# iostm32f105xx register map
Registers are 32-bit, access not given, no defined reset value unless marked. A register's access mark holds for its fields unless they carry their own. Addresses are absolute; registers are grouped by the start of their names; [hi:lo] are bit positions; {n}, {i} and the like mark numbered series.

## UART4
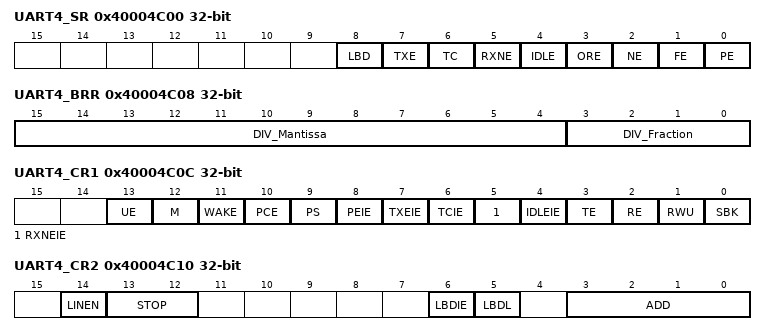
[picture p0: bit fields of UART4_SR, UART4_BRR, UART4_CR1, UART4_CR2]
0x40004C00 UART4_SR
  [8] LBD, [7] TXE, [6] TC, [5] RXNE, [4] IDLE, [3] ORE, [2] NE, [1] FE, [0] PE
0x40004C04 UART4_DR
  [8:0] DR
0x40004C08 UART4_BRR
  [15:4] DIV_Mantissa, [3:0] DIV_Fraction
0x40004C0C UART4_CR1
  [13] UE, [12] M, [11] WAKE, [10] PCE, [9] PS, [8] PEIE, [7] TXEIE, [6] TCIE, [5] RXNEIE, [4] IDLEIE, [3] TE, [2] RE, [1] RWU, [0] SBK
0x40004C10 UART4_CR2
  [14] LINEN, [13:12] STOP, [6] LBDIE, [5] LBDL, [3:0] ADD
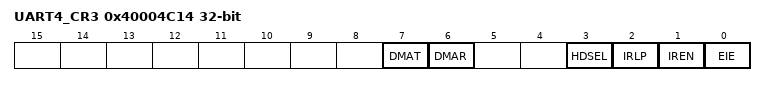
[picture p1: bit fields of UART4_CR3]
0x40004C14 UART4_CR3
  [7] DMAT, [6] DMAR, [3] HDSEL, [2] IRLP, [1] IREN, [0] EIE

## UART5
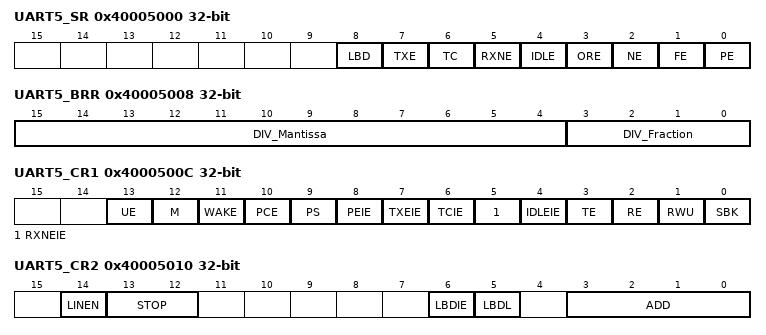
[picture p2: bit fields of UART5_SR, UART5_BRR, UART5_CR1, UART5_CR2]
0x40005000 UART5_SR
  [8] LBD, [7] TXE, [6] TC, [5] RXNE, [4] IDLE, [3] ORE, [2] NE, [1] FE, [0] PE
0x40005004 UART5_DR
  [8:0] DR
0x40005008 UART5_BRR
  [15:4] DIV_Mantissa, [3:0] DIV_Fraction
0x4000500C UART5_CR1
  [13] UE, [12] M, [11] WAKE, [10] PCE, [9] PS, [8] PEIE, [7] TXEIE, [6] TCIE, [5] RXNEIE, [4] IDLEIE, [3] TE, [2] RE, [1] RWU, [0] SBK
0x40005010 UART5_CR2
  [14] LINEN, [13:12] STOP, [6] LBDIE, [5] LBDL, [3:0] ADD
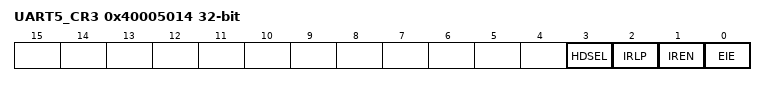
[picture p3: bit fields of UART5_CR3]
0x40005014 UART5_CR3
  [3] HDSEL, [2] IRLP, [1] IREN, [0] EIE

## ADC1
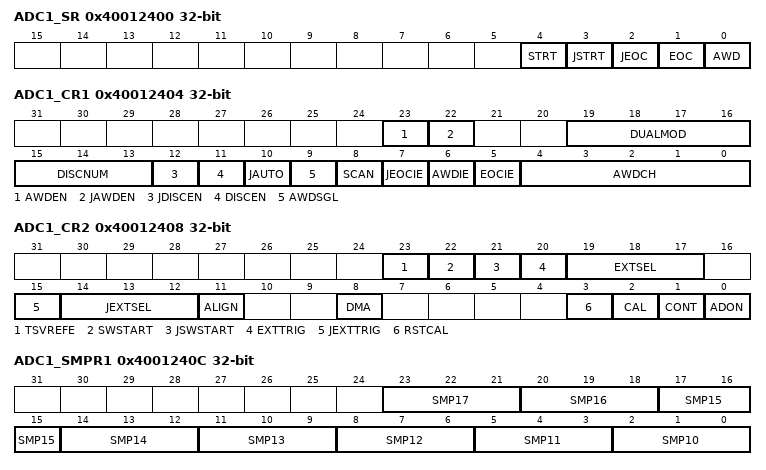
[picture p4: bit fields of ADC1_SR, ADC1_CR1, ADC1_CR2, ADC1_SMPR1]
0x40012400 ADC1_SR
  [4] STRT, [3] JSTRT, [2] JEOC, [1] EOC, [0] AWD
0x40012404 ADC1_CR1
  [23] AWDEN, [22] JAWDEN, [19:16] DUALMOD, [15:13] DISCNUM, [12] JDISCEN, [11] DISCEN, [10] JAUTO, [9] AWDSGL, [8] SCAN, [7] JEOCIE, [6] AWDIE, [5] EOCIE, [4:0] AWDCH
0x40012408 ADC1_CR2
  [23] TSVREFE, [22] SWSTART, [21] JSWSTART, [20] EXTTRIG, [19:17] EXTSEL, [15] JEXTTRIG, [14:12] JEXTSEL, [11] ALIGN, [8] DMA, [3] RSTCAL, [2] CAL, [1] CONT, [0] ADON
0x4001240C ADC1_SMPR1
  [3n-28:3n-30] SMP{n} (n=10..17)
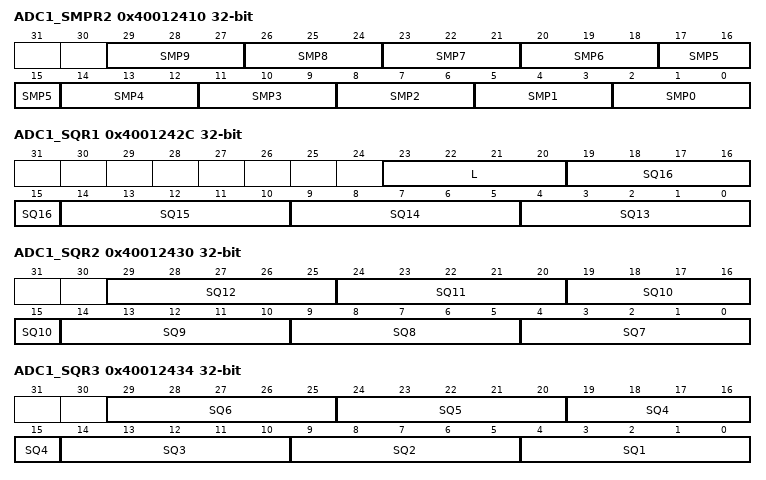
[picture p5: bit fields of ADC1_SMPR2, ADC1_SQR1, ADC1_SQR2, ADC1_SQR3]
0x40012410 ADC1_SMPR2
  [3n+2:3n] SMP{n} (n=0..9)
{0x40012410+4i} ADC1_JOFR{i} (i=1..4)
  [11:0] JOFFSET
0x40012424 ADC1_HTR
  [11:0] HT
0x40012428 ADC1_LTR
  [11:0] LT
0x4001242C ADC1_SQR1
  [23:20] L, [5n-61:5n-65] SQ{n} (n=13..16)
0x40012430 ADC1_SQR2
  [5n-31:5n-35] SQ{n} (n=7..12)
0x40012434 ADC1_SQR3
  [5n-1:5n-5] SQ{n} (n=1..6)
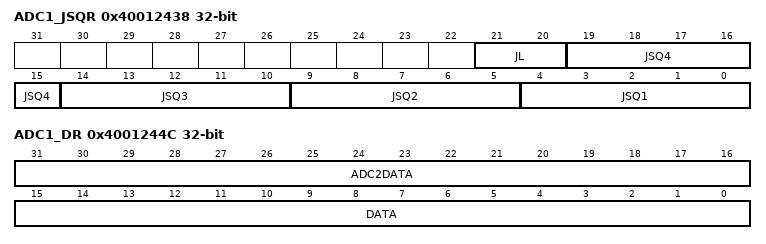
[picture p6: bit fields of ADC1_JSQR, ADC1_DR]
0x40012438 ADC1_JSQR
  [21:20] JL, [5n-1:5n-5] JSQ{n} (n=1..4)
{0x40012438+4i} ADC1_JDR{i} (i=1..4)
  [15:0] JDATA
0x4001244C ADC1_DR
  [31:16] ADC2DATA, [15:0] DATA

## ADC2
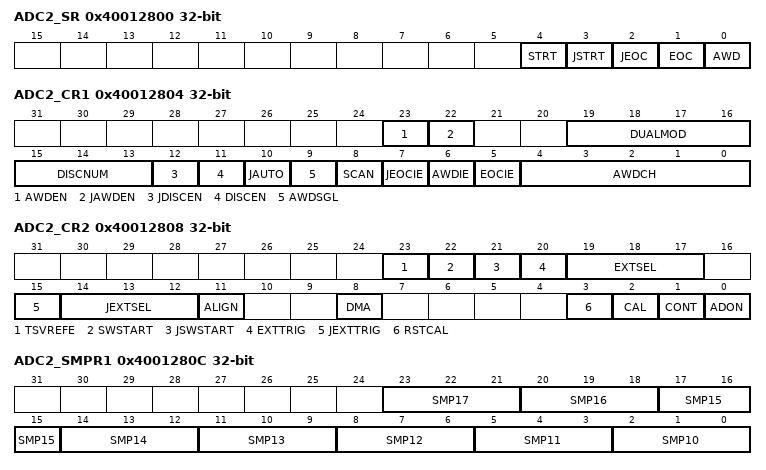
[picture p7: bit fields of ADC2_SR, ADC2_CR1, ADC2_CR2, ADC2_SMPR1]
0x40012800 ADC2_SR
  [4] STRT, [3] JSTRT, [2] JEOC, [1] EOC, [0] AWD
0x40012804 ADC2_CR1
  [23] AWDEN, [22] JAWDEN, [19:16] DUALMOD, [15:13] DISCNUM, [12] JDISCEN, [11] DISCEN, [10] JAUTO, [9] AWDSGL, [8] SCAN, [7] JEOCIE, [6] AWDIE, [5] EOCIE, [4:0] AWDCH
0x40012808 ADC2_CR2
  [23] TSVREFE, [22] SWSTART, [21] JSWSTART, [20] EXTTRIG, [19:17] EXTSEL, [15] JEXTTRIG, [14:12] JEXTSEL, [11] ALIGN, [8] DMA, [3] RSTCAL, [2] CAL, [1] CONT, [0] ADON
0x4001280C ADC2_SMPR1
  [3n-28:3n-30] SMP{n} (n=10..17)
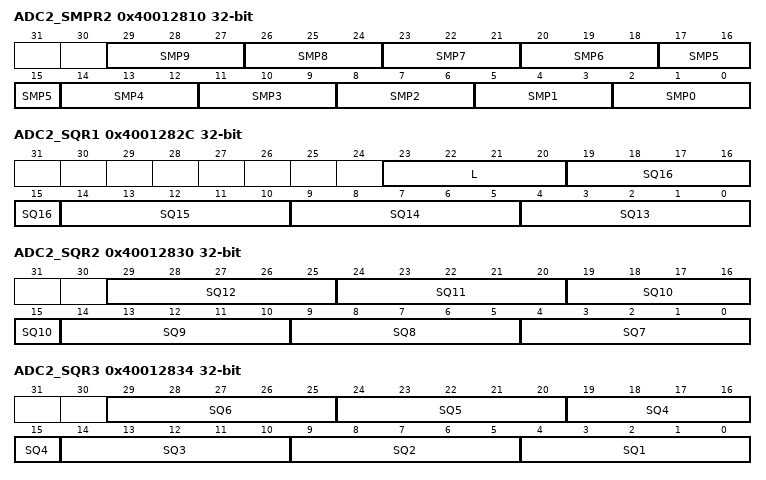
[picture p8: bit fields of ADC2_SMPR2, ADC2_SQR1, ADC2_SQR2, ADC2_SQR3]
0x40012810 ADC2_SMPR2
  [3n+2:3n] SMP{n} (n=0..9)
{0x40012810+4i} ADC2_JOFR{i} (i=1..4)
  [11:0] JOFFSET
0x40012824 ADC2_HTR
  [11:0] HT
0x40012828 ADC2_LTR
  [11:0] LT
0x4001282C ADC2_SQR1
  [23:20] L, [5n-61:5n-65] SQ{n} (n=13..16)
0x40012830 ADC2_SQR2
  [5n-31:5n-35] SQ{n} (n=7..12)
0x40012834 ADC2_SQR3
  [5n-1:5n-5] SQ{n} (n=1..6)
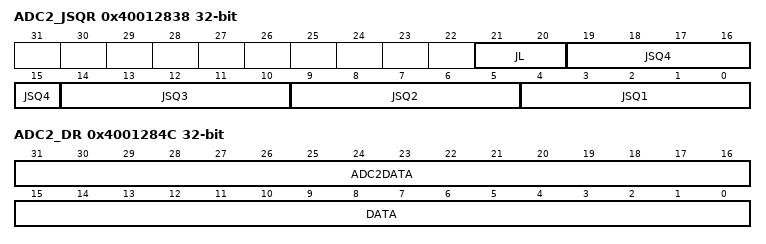
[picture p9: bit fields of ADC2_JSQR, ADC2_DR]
0x40012838 ADC2_JSQR
  [21:20] JL, [5n-1:5n-5] JSQ{n} (n=1..4)
{0x40012838+4i} ADC2_JDR{i} (i=1..4)
  [15:0] JDATA
0x4001284C ADC2_DR
  [31:16] ADC2DATA, [15:0] DATA

## DAC
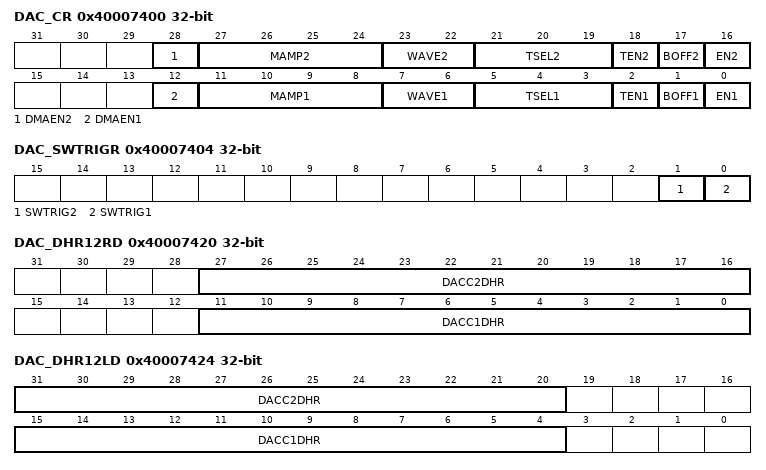
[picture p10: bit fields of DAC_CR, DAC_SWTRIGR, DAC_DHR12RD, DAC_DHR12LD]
0x40007400 DAC_CR
  [28] DMAEN2, [27:24] MAMP2, [23:22] WAVE2, [21:19] TSEL2, [18] TEN2, [17] BOFF2, [16] EN2, [12] DMAEN1, [11:8] MAMP1, [7:6] WAVE1, [5:3] TSEL1, [2] TEN1, [1] BOFF1, [0] EN1
0x40007404 DAC_SWTRIGR
  [1] SWTRIG2, [0] SWTRIG1
0x40007408 DAC_DHR12R1
  [11:0] DACC1DHR
0x4000740C DAC_DHR12L1
  [15:4] DACC1DHR
0x40007410 DAC_DHR8R1
  [7:0] DACC1DHR
0x40007414 DAC_DHR12R2
  [11:0] DACC2DHR
0x40007418 DAC_DHR12L2
  [15:4] DACC2DHR
0x4000741C DAC_DHR8R2
  [7:0] DACC2DHR
0x40007420 DAC_DHR12RD
  [27:16] DACC2DHR, [11:0] DACC1DHR
0x40007424 DAC_DHR12LD
  [31:20] DACC2DHR, [15:4] DACC1DHR
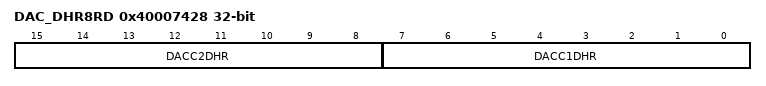
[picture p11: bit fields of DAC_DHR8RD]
0x40007428 DAC_DHR8RD
  [15:8] DACC2DHR, [7:0] DACC1DHR
0x4000742C DAC_DOR1
  [11:0] DACC1DOR
0x40007430 DAC_DOR2
  [11:0] DACC2DOR

## FLASH
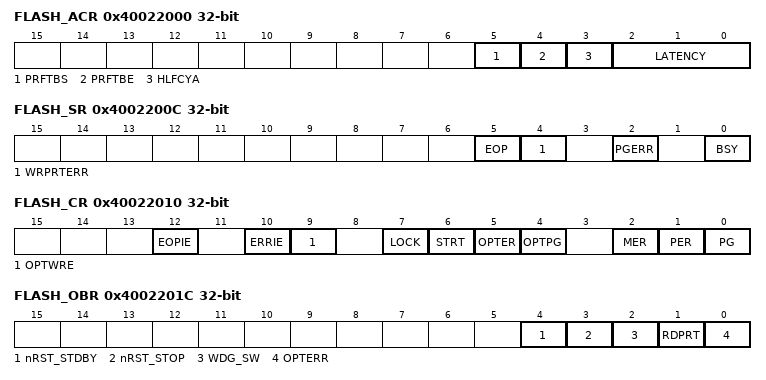
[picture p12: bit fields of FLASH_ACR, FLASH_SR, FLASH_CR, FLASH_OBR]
0x40022000 FLASH_ACR
  [5] PRFTBS, [4] PRFTBE, [3] HLFCYA, [2:0] LATENCY
0x40022004 FLASH_KEYR
0x40022008 FLASH_OPTKEYR
0x4002200C FLASH_SR
  [5] EOP, [4] WRPRTERR, [2] PGERR, [0] BSY
0x40022010 FLASH_CR
  [12] EOPIE, [10] ERRIE, [9] OPTWRE, [7] LOCK, [6] STRT, [5] OPTER, [4] OPTPG, [2] MER, [1] PER, [0] PG
0x40022014 FLASH_AR
0x4002201C FLASH_OBR
  [4] nRST_STDBY, [3] nRST_STOP, [2] WDG_SW, [1] RDPRT, [0] OPTERR
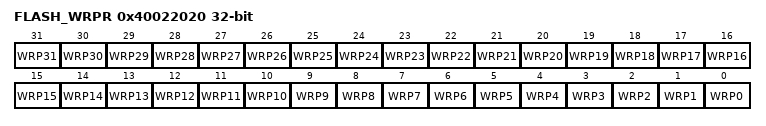
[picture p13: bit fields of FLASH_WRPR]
0x40022020 FLASH_WRPR
  [n] WRP{n} (n=0..31)

## CRC
0x40023000 CRC_DR
0x40023004 CRC_IDR
  [7:0] IDR
0x40023008 CRC_CR
  [0] RESET
